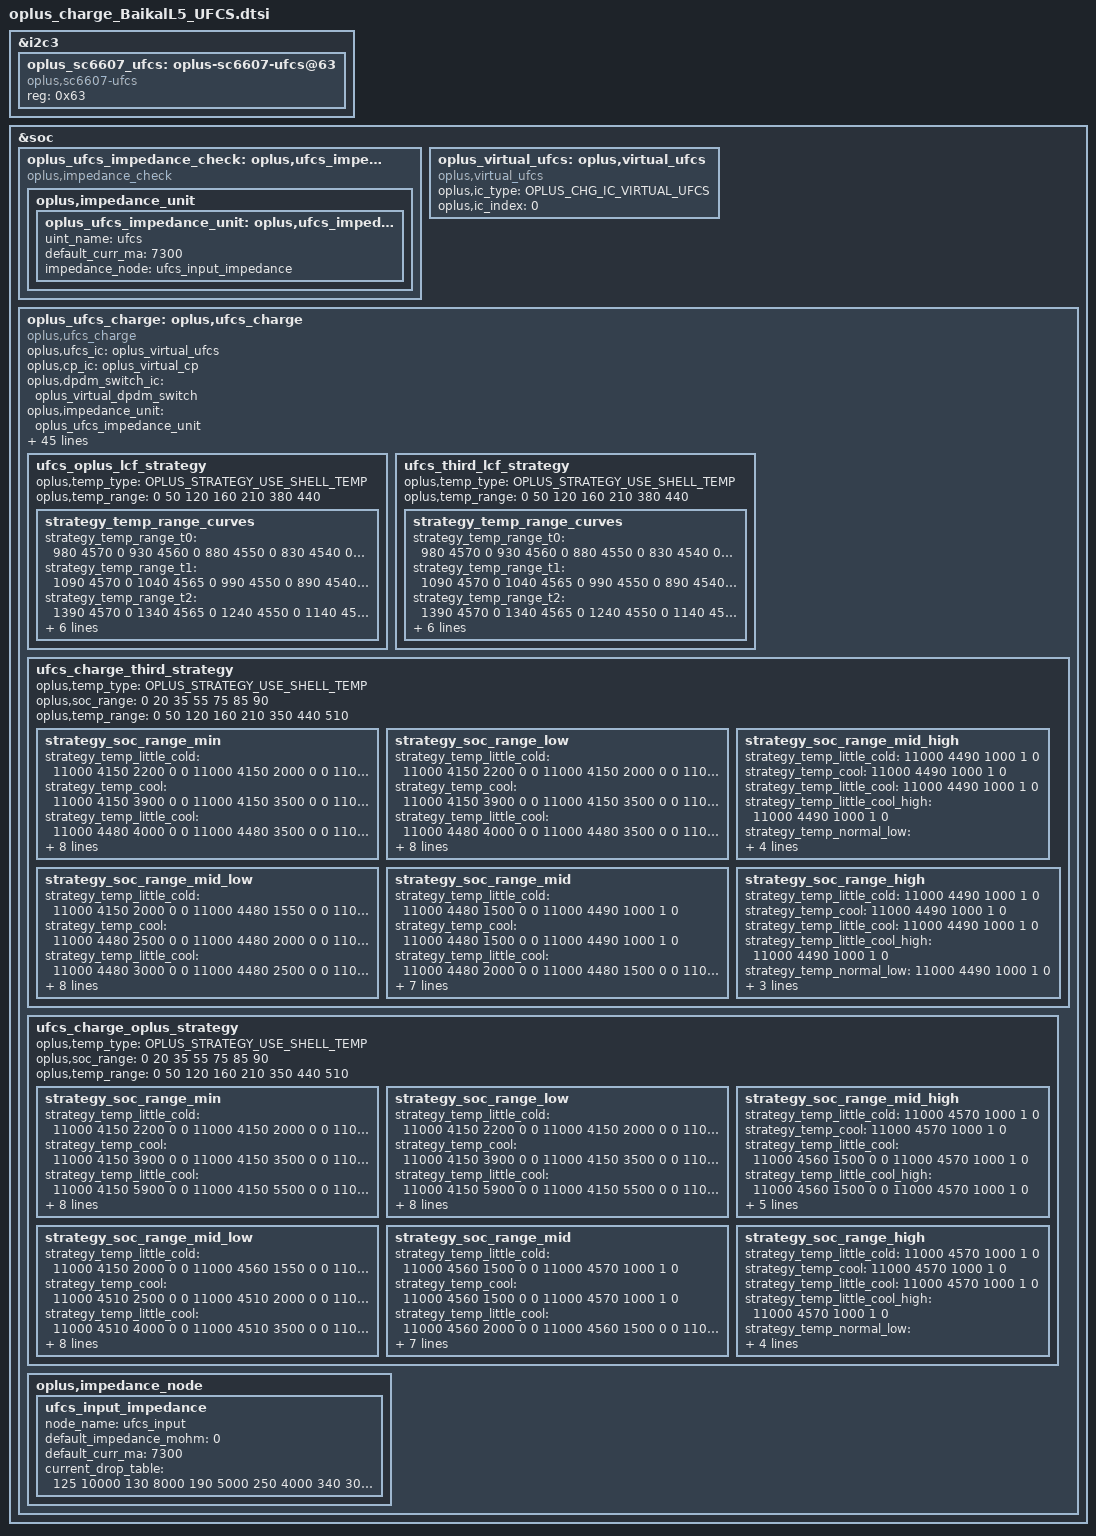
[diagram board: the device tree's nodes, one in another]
&i2c3 {
	oplus_sc6607_ufcs:oplus-sc6607-ufcs@63 {
		status = "okay";
		compatible = "oplus,sc6607-ufcs";
		reg = <0x63>;
	};
};

&soc {
	oplus_ufcs_impedance_check: oplus,ufcs_impedance_check {
		compatible = "oplus,impedance_check";
		oplus,impedance_unit {
			oplus_ufcs_impedance_unit: oplus,ufcs_impedance_unit {
				uint_name = "ufcs";
				default_curr_ma = <7300>;
				impedance_node = <&ufcs_input_impedance>;
			};
		};
	};

	oplus_virtual_ufcs: oplus,virtual_ufcs {
		compatible = "oplus,virtual_ufcs";

		oplus,ic_type = <OPLUS_CHG_IC_VIRTUAL_UFCS>;
		oplus,ic_index = <0>;
	};

	oplus_ufcs_charge: oplus,ufcs_charge {
		compatible = "oplus,ufcs_charge";
		oplus,ufcs_ic = <&oplus_virtual_ufcs>;
		oplus,cp_ic = <&oplus_virtual_cp>;
		oplus,dpdm_switch_ic = <&oplus_virtual_dpdm_switch>;

		oplus,impedance_unit = <&oplus_ufcs_impedance_unit>;

		oplus,plc_strategy-data = <&oplus_ufcs_step_strategy &cp_2t1_simple_strategy>;
		oplus,plc_strategy-names = "default", "third";

		oplus,target_vbus_mv = <11000>;
		oplus,curr_max_ma = <7300>;
		oplus,curr_table_type = <UFCS_CURR_CP_TABLE>;
		oplus,high_imp_compensation_setting_mv = <250>;
		oplus,upper_compensation_mv = <200>;
		oplus,lift_vbus_use_cpvout;
		oplus,subboard_ntc_abnormal_current = <4000>;
		oplus,ufcs_need_reset_adapter;

		oplus,ufcs_warm_allow_vol = <4000>;
		oplus,ufcs_warm_allow_soc = <55>;
		oplus,ufcs_strategy_normal_current = <7300>;
		oplus,ufcs_over_high_or_low_current = <7300>;
		oplus,ufcs_timeout_third = <17537>;
		oplus,ufcs_timeout_oplus = <17537>;
		oplus,ufcs_ibat_over_third = <9400>;
		oplus,ufcs_ibat_over_oplus = <16000>;
		oplus,ufcs_full_cool_sw_vbat = <4570>;
		oplus,ufcs_full_normal_sw_vbat = <4570>;
		oplus,ufcs_full_normal_hw_vbat = <4580>;
		oplus,ufcs_full_ffc_vbat = <4520>;
		oplus,ufcs_full_warm_vbat = <4130>;
		oplus,ufcs_full_cool_sw_vbat_third = <4490>;
		oplus,ufcs_full_normal_sw_vbat_third= <4490>;
		oplus,ufcs_full_normal_hw_vbat_third = <4500>;
		oplus,ufcs_current_change_timeout = <100>;
		oplus,ufcs_strategy_batt_high_temp = <405 420 430 395 410 425>;
		oplus,ufcs_strategy_high_current = <5000 4000 3000 3000 4000 5000>;
		oplus,ufcs_little_cool_high_temp = <210>;
		oplus,curve_strategy_name = "pps_ufcs_curve_v2";
		oplus_spec,ufcs_low_temp = <0>;
		oplus_spec,ufcs_high_temp = <500>;
		oplus_spec,ufcs_low_soc = <0>;
		oplus_spec,ufcs_high_soc = <90>;
		oplus_spec,ufcs_high_soc_third = <85>;
		oplus,ufcs_charge_strategy_temp = <0 50 120 160 350 440 510>;
        oplus,temperature_strategy_name = "cgcl";
        oplus,temperature_strategy_data = <OPLUS_STRATEGY_USE_SHELL_TEMP
                                                0   385 7300 1 0
                                                375 405 5000 2 0
                                                395 420 4000 3 1
                                                410 430 3500 4 2
                                                420 440 2000 4 3>;
		ufcs_oplus_lcf_strategy {
			oplus,temp_type = <OPLUS_STRATEGY_USE_SHELL_TEMP>;
			oplus,temp_range = <0 50 120 160 210 380 440>;

			strategy_temp_range_curves {
				strategy_temp_range_t0 =	<980 4570 0
								 930 4560 0
								 880 4550 0
								 830 4540 0
								 780 4530 1>;
				strategy_temp_range_t1 =	<1090 4570 0
								 1040 4565 0
								 990 4550 0
								 890 4540 0
								 790 4530 1>;
				strategy_temp_range_t2 =	<1390 4570 0
								 1340 4565 0
								 1240 4550 0
								 1140 4540 0
								 990 4530 1>;
				strategy_temp_range_t3 =	<1390 4570 0
								 1340 4565 0
								 1240 4550 0
								 1140 4540 0
								 990 4530 1>;
				strategy_temp_range_t4 =	<2250 4553 0
								 2050 4538 0
								 1700 4524 0
								 1350 4510 0
								 1000 4490 1>;
				strategy_temp_range_t5 =	<2850 4558 0
								 2650 4550 0
								 2100 4532 0
								 1550 4510 0
								 1000 4490 1>;
			};
		};

		ufcs_third_lcf_strategy {
			oplus,temp_type = <OPLUS_STRATEGY_USE_SHELL_TEMP>;
			oplus,temp_range = <0 50 120 160 210 380 440>;

			strategy_temp_range_curves {
				strategy_temp_range_t0 =	<980 4570 0
								 930 4560 0
								 880 4550 0
								 830 4540 0
								 780 4530 1>;
				strategy_temp_range_t1 =	<1090 4570 0
								 1040 4565 0
								 990 4550 0
								 890 4540 0
								 790 4530 1>;
				strategy_temp_range_t2 =	<1390 4570 0
								 1340 4565 0
								 1240 4550 0
								 1140 4540 0
								 990 4530 1>;
				strategy_temp_range_t3 =	<1390 4570 0
								 1340 4565 0
								 1240 4550 0
								 1140 4540 0
								 990 4530 1>;
				strategy_temp_range_t4 =	<2250 4558 0
								 2100 4550 0
								 1900 4541 0
								 1700 4532 0
								 1500 4510 1>;
				strategy_temp_range_t5 =	<2850 4558 0
								 2650 4550 0
								 2100 4532 0
								 1550 4510 0
								 1000 4490 1>;
			};
		};

		ufcs_charge_third_strategy {
			oplus,temp_type = <OPLUS_STRATEGY_USE_SHELL_TEMP>;
			oplus,soc_range = <0 20 35 55 75 85 90>;
			oplus,temp_range = <0 50 120 160 210 350 440 510>;

			strategy_soc_range_min {
				strategy_temp_little_cold =	<11000 4150 2200 0 0
								11000 4150 2000 0 0
								11000 4480 1550 0 0
								11000 4480 1500 0 0
								11000 4490 1000 1 0>;
				strategy_temp_cool =		<11000 4150 3900 0 0
								11000 4150 3500 0 0
								11000 4150 3000 0 0
								11000 4480 2900 0 0
								11000 4480 2500 0 0
								11000 4480 2000 0 0
								11000 4480 1550 0 0
								11000 4480 1500 0 0
								11000 4490 1000 1 0>;
				strategy_temp_little_cool =	<11000 4480 4000 0 0
								11000 4480 3500 0 0
								11000 4480 3250 0 0
								11000 4480 3000 0 0
								11000 4480 2500 0 0
								11000 4480 2000 0 0
								11000 4480 1500 0 0
								11000 4490 1000 1 0>;
				strategy_temp_little_cool_high =	<11000 4480 4000 0 0
								11000 4480 3500 0 0
								11000 4480 3250 0 0
								11000 4480 3000 0 0
								11000 4480 2500 0 0
								11000 4480 2000 0 0
								11000 4480 1500 0 0
								11000 4490 1000 1 0>;
				strategy_temp_normal_low =	<11000 4480 4000 0 0
								11000 4480 3600 0 0
								11000 4480 3500 0 0
								11000 4480 3000 0 0
								11000 4480 2500 0 0
								11000 4480 2000 0 0
								11000 4480 1500 0 0
								11000 4490 1000 1 0>;
				strategy_temp_normal_high =	<11000 4460 4000 0 0
								11000 4460 3600 0 0
								11000 4460 3500 0 0
								11000 4460 3000 0 0
								11000 4460 2500 0 0
								11000 4460 2000 0 0
								11000 4460 1500 0 0
								11000 4470 1000 1 0>;
				strategy_temp_warm =		<11000 4120 1850 0 0
								11000 4120 1500 0 0
								11000 4130 1000 1 0>;
			};
			strategy_soc_range_low {
				strategy_temp_little_cold =	<11000 4150 2200 0 0
								11000 4150 2000 0 0
								11000 4480 1550 0 0
								11000 4480 1500 0 0
								11000 4490 1000 1 0>;
				strategy_temp_cool =		<11000 4150 3900 0 0
								11000 4150 3500 0 0
								11000 4150 3000 0 0
								11000 4480 2900 0 0
								11000 4480 2500 0 0
								11000 4480 2000 0 0
								11000 4480 1550 0 0
								11000 4480 1500 0 0
								11000 4490 1000 1 0>;
				strategy_temp_little_cool =	<11000 4480 4000 0 0
								11000 4480 3500 0 0
								11000 4480 3250 0 0
								11000 4480 3000 0 0
								11000 4480 2500 0 0
								11000 4480 2000 0 0
								11000 4480 1500 0 0
								11000 4490 1000 1 0>;
				strategy_temp_little_cool_high =	<11000 4480 4000 0 0
								11000 4480 3600 0 0
								11000 4480 3500 0 0
								11000 4480 3000 0 0
								11000 4480 2500 0 0
								11000 4480 2000 0 0
								11000 4480 1500 0 0
								11000 4490 1000 1 0>;
				strategy_temp_normal_low =	<11000 4480 4000 0 0
								11000 4480 3600 0 0
								11000 4480 3500 0 0
								11000 4480 3000 0 0
								11000 4480 2500 0 0
								11000 4480 2000 0 0
								11000 4480 1500 0 0
								11000 4490 1000 1 0>;
				strategy_temp_normal_high =	<11000 4460 4000 0 0
								11000 4460 3600 0 0
								11000 4460 3500 0 0
								11000 4460 3000 0 0
								11000 4460 2500 0 0
								11000 4460 2000 0 0
								11000 4460 1500 0 0
								11000 4470 1000 1 0>;
				strategy_temp_warm =		<11000 4120 1850 0 0
								11000 4120 1500 0 0
								11000 4130 1000 1 0>;
			};
			strategy_soc_range_mid_low {
				strategy_temp_little_cold =	<11000 4150 2000 0 0
								11000 4480 1550 0 0
								11000 4480 1500 0 0
								11000 4490 1000 1 0>;
				strategy_temp_cool =		<11000 4480 2500 0 0
								11000 4480 2000 0 0
								11000 4480 1550 0 0
								11000 4480 1500 0 0
								11000 4490 1000 1 0>;
				strategy_temp_little_cool =	<11000 4480 3000 0 0
								11000 4480 2500 0 0
								11000 4480 2000 0 0
								11000 4480 1500 0 0
								11000 4490 1000 1 0>;
				strategy_temp_little_cool_high =	<11000 4480 3000 0 0
								11000 4480 2500 0 0
								11000 4480 2000 0 0
								11000 4480 1500 0 0
								11000 4490 1000 1 0>;
				strategy_temp_normal_low =	<11000 4480 4000 0 0
								11000 4480 3600 0 0
								11000 4480 3500 0 0
								11000 4480 3000 0 0
								11000 4480 2500 0 0
								11000 4480 2000 0 0
								11000 4480 1500 0 0
								11000 4490 1000 1 0>;
				strategy_temp_normal_high =	<11000 4460 4000 0 0
								11000 4460 3600 0 0
								11000 4460 3500 0 0
								11000 4460 3000 0 0
								11000 4460 2500 0 0
								11000 4460 2000 0 0
								11000 4460 1500 0 0
								11000 4470 1000 1 0>;
				strategy_temp_warm =		<11000 4120 1850 0 0
								11000 4120 1500 0 0
								11000 4130 1000 1 0>;
			};
			strategy_soc_range_mid {
				strategy_temp_little_cold =	<11000 4480 1500 0 0
								11000 4490 1000 1 0>;
				strategy_temp_cool =		<11000 4480 1500 0 0
								11000 4490 1000 1 0>;
				strategy_temp_little_cool =	<11000 4480 2000 0 0
								11000 4480 1500 0 0
								11000 4490 1000 1 0>;
				strategy_temp_little_cool_high =	<11000 4480 2000 0 0
								11000 4480 1500 0 0
								11000 4490 1000 1 0>;
				strategy_temp_normal_low =	<11000 4480 2000 0 0
								11000 4480 1500 0 0
								11000 4490 1000 1 0>;
				strategy_temp_normal_high =	<11000 4460 2500 0 0
								11000 4460 2000 0 0
								11000 4460 1500 0 0
								11000 4470 1000 1 0>;
				strategy_temp_warm =		<11000 4130 1000 1 0>;
			};
			strategy_soc_range_mid_high {
				strategy_temp_little_cold =	<11000 4490 1000 1 0>;
				strategy_temp_cool =		<11000 4490 1000 1 0>;
				strategy_temp_little_cool =	<11000 4490 1000 1 0>;
				strategy_temp_little_cool_high =	<11000 4490 1000 1 0>;
				strategy_temp_normal_low =	<11000 4480 1500 0 0
								11000 4490 1000 1 0>;
				strategy_temp_normal_high =	<11000 4480 1500 0 0
								11000 4490 1000 1 0>;
				strategy_temp_warm =		<11000 4130 1000 1 0>;
			};
			strategy_soc_range_high {
				strategy_temp_little_cold =	<11000 4490 1000 1 0>;
				strategy_temp_cool =		<11000 4490 1000 1 0>;
				strategy_temp_little_cool =	<11000 4490 1000 1 0>;
				strategy_temp_little_cool_high =	<11000 4490 1000 1 0>;
				strategy_temp_normal_low =	<11000 4490 1000 1 0>;
				strategy_temp_normal_high =	<11000 4460 1500 0 0
								11000 4470 1000 1 0>;
				strategy_temp_warm =		<11000 4130 1000 1 0>;
			};
		};

		ufcs_charge_oplus_strategy {
			oplus,temp_type = <OPLUS_STRATEGY_USE_SHELL_TEMP>;
			oplus,soc_range = <0 20 35 55 75 85 90>;
			oplus,temp_range = <0 50 120 160 210 350 440 510>;

			strategy_soc_range_min {
				strategy_temp_little_cold =	<11000 4150 2200 0 0
								11000 4150 2000 0 0
								11000 4560 1550 0 0
								11000 4560 1500 0 0
								11000 4570 1000 1 0>;
				strategy_temp_cool =		<11000 4150 3900 0 0
								11000 4150 3500 0 0
								11000 4150 3000 0 0
								11000 4510 2900 0 0
								11000 4510 2500 0 0
								11000 4510 2000 0 0
								11000 4560 1550 0 0
								11000 4560 1500 0 0
								11000 4570 1000 1 0>;
				strategy_temp_little_cool =	<11000 4150 5900 0 0
								11000 4150 5500 0 0
								11000 4150 5000 0 0
								11000 4510 4250 0 0
								11000 4510 4000 0 0
								11000 4510 3500 0 0
								11000 4560 3250 0 0
								11000 4560 3000 0 0
								11000 4560 2500 0 0
								11000 4560 2000 0 0
								11000 4560 1500 0 0
								11000 4570 1000 1 0>;
				strategy_temp_little_cool_high =	<11000 4150 5900 0 0
								11000 4150 5500 0 0
								11000 4150 5000 0 0
								11000 4510 4250 0 0
								11000 4510 4000 0 0
								11000 4510 3500 0 0
								11000 4560 3250 0 0
								11000 4560 3000 0 0
								11000 4560 2500 0 0
								11000 4560 2000 0 0
								11000 4560 1500 0 0
								11000 4570 1000 1 0>;
				strategy_temp_normal_low =	<11000 4250 7300 0 0
								11000 4280 6550 0 0
								11000 4280 5000 0 0
								11000 4510 4550 0 0
								11000 4510 4000 0 0
								11000 4560 3600 0 0
								11000 4560 3500 0 0
								11000 4560 3000 0 0
								11000 4560 2500 0 0
								11000 4560 2000 0 0
								11000 4560 1500 0 0
								11000 4565 1200 0 0
								11000 4550 1000 1 0>;
				strategy_temp_normal_high =	<11000 4250 7300 0 0
								11000 4280 6550 0 0
								11000 4280 5000 0 0
								11000 4510 4550 0 0
								11000 4510 4000 0 0
								11000 4560 3600 0 0
								11000 4560 3500 0 0
								11000 4560 3000 0 0
								11000 4560 2500 0 0
								11000 4560 2000 0 0
								11000 4565 1500 0 0
								11000 4550 1200 0 0
								11000 4550 1000 1 0>;
				strategy_temp_warm =		<11000 4120 1850 0 0
								11000 4120 1500 0 0
								11000 4130 1000 1 0>;
			};
			strategy_soc_range_low {
				strategy_temp_little_cold =	<11000 4150 2200 0 0
								11000 4150 2000 0 0
								11000 4560 1550 0 0
								11000 4560 1500 0 0
								11000 4570 1000 1 0>;
				strategy_temp_cool =		<11000 4150 3900 0 0
								11000 4150 3500 0 0
								11000 4150 3000 0 0
								11000 4510 2900 0 0
								11000 4510 2500 0 0
								11000 4510 2000 0 0
								11000 4560 1550 0 0
								11000 4560 1500 0 0
								11000 4570 1000 1 0>;
				strategy_temp_little_cool =	<11000 4150 5900 0 0
								11000 4150 5500 0 0
								11000 4150 5000 0 0
								11000 4510 4250 0 0
								11000 4510 4000 0 0
								11000 4510 3500 0 0
								11000 4560 3250 0 0
								11000 4560 3000 0 0
								11000 4560 2500 0 0
								11000 4560 2000 0 0
								11000 4560 1500 0 0
								11000 4570 1000 1 0>;
				strategy_temp_little_cool_high =	<11000 4150 5900 0 0
								11000 4150 5500 0 0
								11000 4150 5000 0 0
								11000 4510 4250 0 0
								11000 4510 4000 0 0
								11000 4510 3500 0 0
								11000 4560 3250 0 0
								11000 4560 3000 0 0
								11000 4560 2500 0 0
								11000 4560 2000 0 0
								11000 4560 1500 0 0
								11000 4570 1000 1 0>;
				strategy_temp_normal_low =	<11000 4250 7300 0 0
								11000 4280 6550 0 0
								11000 4280 5000 0 0
								11000 4510 4550 0 0
								11000 4510 4000 0 0
								11000 4560 3600 0 0
								11000 4560 3500 0 0
								11000 4560 3000 0 0
								11000 4560 2500 0 0
								11000 4560 2000 0 0
								11000 4560 1500 0 0
								11000 4565 1200 0 0
								11000 4550 1000 1 0>;
				strategy_temp_normal_high =	<11000 4250 7300 0 0
								11000 4280 6550 0 0
								11000 4280 5000 0 0
								11000 4510 4550 0 0
								11000 4510 4000 0 0
								11000 4560 3600 0 0
								11000 4560 3500 0 0
								11000 4560 3000 0 0
								11000 4560 2500 0 0
								11000 4560 2000 0 0
								11000 4565 1500 0 0
								11000 4550 1200 0 0
								11000 4550 1000 1 0>;
				strategy_temp_warm =		<11000 4120 1850 0 0
								11000 4120 1500 0 0
								11000 4130 1000 1 0>;
			};
			strategy_soc_range_mid_low {
				strategy_temp_little_cold =	<11000 4150 2000 0 0
								11000 4560 1550 0 0
								11000 4560 1500 0 0
								11000 4570 1000 1 0>;
				strategy_temp_cool =		<11000 4510 2500 0 0
								11000 4510 2000 0 0
								11000 4560 1550 0 0
								11000 4560 1500 0 0
								11000 4570 1000 1 0>;
				strategy_temp_little_cool =	<11000 4510 4000 0 0
								11000 4510 3500 0 0
								11000 4560 3250 0 0
								11000 4560 3000 0 0
								11000 4560 2500 0 0
								11000 4560 2000 0 0
								11000 4560 1500 0 0
								11000 4570 1000 1 0>;
				strategy_temp_little_cool_high =	<11000 4510 4000 0 0
								11000 4510 3500 0 0
								11000 4560 3250 0 0
								11000 4560 3000 0 0
								11000 4560 2500 0 0
								11000 4560 2000 0 0
								11000 4560 1500 0 0
								11000 4570 1000 1 0>;
				strategy_temp_normal_low =	<11000 4250 7300 0 0
								11000 4280 6550 0 0
								11000 4280 5000 0 0
								11000 4510 4550 0 0
								11000 4510 4000 0 0
								11000 4560 3600 0 0
								11000 4560 3500 0 0
								11000 4560 3000 0 0
								11000 4560 2500 0 0
								11000 4560 2000 0 0
								11000 4560 1500 0 0
								11000 4565 1200 0 0
								11000 4550 1000 1 0>;
				strategy_temp_normal_high =	<11000 4250 7300 0 0
								11000 4280 6550 0 0
								11000 4280 5000 0 0
								11000 4510 4550 0 0
								11000 4510 4000 0 0
								11000 4560 3600 0 0
								11000 4560 3500 0 0
								11000 4560 3000 0 0
								11000 4560 2500 0 0
								11000 4560 2000 0 0
								11000 4565 1500 0 0
								11000 4550 1200 0 0
								11000 4550 1000 1 0>;
				strategy_temp_warm =		<11000 4120 1850 0 0
								11000 4120 1500 0 0
								11000 4130 1000 1 0>;
			};
			strategy_soc_range_mid {
				strategy_temp_little_cold =	<11000 4560 1500 0 0
								11000 4570 1000 1 0>;
				strategy_temp_cool =		<11000 4560 1500 0 0
								11000 4570 1000 1 0>;
				strategy_temp_little_cool =	<11000 4560 2000 0 0
								11000 4560 1500 0 0
								11000 4570 1000 1 0>;
				strategy_temp_little_cool_high =	<11000 4560 2000 0 0
								11000 4560 1500 0 0
								11000 4570 1000 1 0>;
				strategy_temp_normal_low =	<11000 4560 2500 0 0
								11000 4560 2000 0 0
								11000 4560 1500 0 0
								11000 4565 1200 0 0
								11000 4550 1000 1 0>;
				strategy_temp_normal_high =	<11000 4560 3000 0 0
								11000 4560 2500 0 0
								11000 4560 2000 0 0
								11000 4565 1500 0 0
								11000 4550 1200 0 0
								11000 4550 1000 1 0>;
				strategy_temp_warm =		<11000 4130 1000 1 0>;
			};
			strategy_soc_range_mid_high {
				strategy_temp_little_cold =	<11000 4570 1000 1 0>;
				strategy_temp_cool =		<11000 4570 1000 1 0>;
				strategy_temp_little_cool =	<11000 4560 1500 0 0
								11000 4570 1000 1 0>;
				strategy_temp_little_cool_high =	<11000 4560 1500 0 0
								11000 4570 1000 1 0>;
				strategy_temp_normal_low =<11000 4565 1500 0 0
								11000 4565 1200 0 0
								11000 4550 1000 1 0>;
				strategy_temp_normal_high =	<11000 4560 2000 0 0
								11000 4565 1500 0 0
								11000 4550 1200 0 0
								11000 4550 1000 1 0>;
				strategy_temp_warm =		<11000 4130 1000 1 0>;
			};
			strategy_soc_range_high {
				strategy_temp_little_cold =	<11000 4570 1000 1 0>;
				strategy_temp_cool =		<11000 4570 1000 1 0>;
				strategy_temp_little_cool =	<11000 4570 1000 1 0>;
				strategy_temp_little_cool_high =	<11000 4570 1000 1 0>;
				strategy_temp_normal_low =	<11000 4565 1200 0 0
								11000 4550 1000 1 0>;
				strategy_temp_normal_high =	<11000 4565 1500 0 0
								11000 4550 1200 0 0
								11000 4550 1000 1 0>;
				strategy_temp_warm =		<11000 4130 1000 1 0>;
			};
		};


		oplus,impedance_node {
			ufcs_input_impedance: ufcs_input_impedance {
				node_name = "ufcs_input";
				default_impedance_mohm = <0>;
				default_curr_ma = <7300>;
				current_drop_table = <
					125  10000
					130  8000
					190  5000
					250  4000
					340  3000
					380  2000
					480 0
				>;
			};
		};
	};
};
